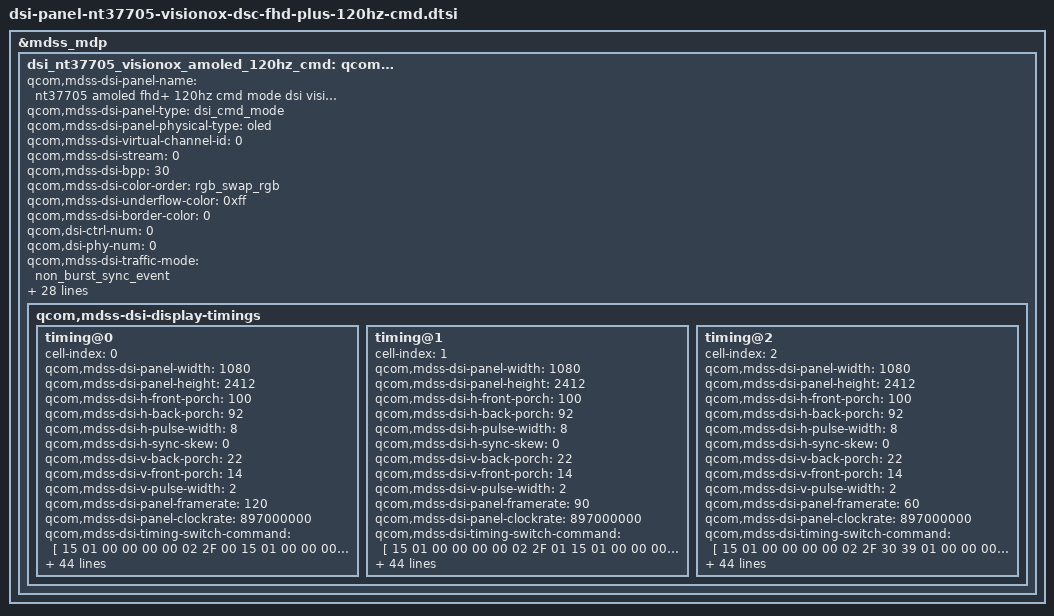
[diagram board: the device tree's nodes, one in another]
//OP Manual
//2023/5/12 update OP Manual v13
//1.switch DBV when Skip Frame 60hz/90hz, refresh rate will be changed to 60hz/90hz
//2023/4/25 update OP Manual v12
//1.add 51h setting code, it takes effects at second frame when write 51h
//2023/4/21 update OP Manual v11
//1.update Skip Frame mode setting code
//2023/4/20 update OP Manual v10
//1.update RCN code
//2.modify delay to 100ms after 11 code
//2023/3/30 update OP Manual v09
//1.update enter aod code and aod brightness code
//2023/3/13 update OP Manual v08
//1.update Skip Frame code
//2023/3/10 update OP Manual v07
//1.update OSC Tracking code
//2.enter Skip Frame mode when changing DBV, frequency returns to 120hz
//2023/2/27 update OP Manual v06
//1.add RCN code
//2023/2/14 update OP Manual v05
//1.modify enter/exit aod code
//2.modify skip frame CLKN code
//2023/2/6 update OP Manual v04
//1.Idle skip mode sequence: 30Hz(Repeat 1 times) --> 1Hz
//2.set OD ON
//3.add OSC tracking
//4.add skip frame CLKN slow down code(to solve esd issue)
//5.modify enter/exit aod code
//6.set DBV dimming OFF

&mdss_mdp {
	dsi_nt37705_visionox_amoled_120hz_cmd:
		qcom,mdss_dsi_nt37705_visionox_amoled_120hz_cmd {
		qcom,mdss-dsi-panel-name =
			"nt37705 amoled fhd+ 120hz cmd mode dsi visionox panel";
		qcom,mdss-dsi-panel-type = "dsi_cmd_mode";
		qcom,mdss-dsi-panel-physical-type = "oled";
		qcom,mdss-dsi-virtual-channel-id = <0>;
		qcom,mdss-dsi-stream = <0>;
		qcom,mdss-dsi-bpp = <30>;
		qcom,mdss-dsi-color-order = "rgb_swap_rgb";
		qcom,mdss-dsi-underflow-color = <0xff>;
		qcom,mdss-dsi-border-color = <0>;

		qcom,dsi-ctrl-num = <0>;
		qcom,dsi-phy-num = <0>;

		qcom,mdss-dsi-traffic-mode = "non_burst_sync_event";
		qcom,mdss-dsi-lane-map = "lane_map_0123";
		qcom,mdss-dsi-bllp-eof-power-mode;
		qcom,mdss-dsi-bllp-power-mode;
		qcom,mdss-dsi-lane-0-state;
		qcom,mdss-dsi-lane-1-state;
		qcom,mdss-dsi-lane-2-state;
		qcom,mdss-dsi-lane-3-state;
		qcom,mdss-dsi-dma-trigger = "trigger_sw";
		qcom,mdss-dsi-mdp-trigger = "none";
		qcom,mdss-dsi-lp11-init;
		qcom,mdss-dsi-reset-sequence = <1 10>, <0 1>, <1 20>;
		qcom,mdss-pan-physical-width-dimension = <69>;
		qcom,mdss-pan-physical-height-dimension = <156>;
		qcom,mdss-dsi-tx-eot-append;
		qcom,mdss-dsi-rx-eot-ignore;

		qcom,mdss-dsi-panel-hdr-enabled;
		qcom,mdss-dsi-panel-hdr-color-primaries = <14500 15500 32000
						17000 15500 30000 8000 3000>;
		qcom,mdss-dsi-panel-peak-brightness = <4200000>;
		qcom,mdss-dsi-panel-blackness-level = <3230>;

		qcom,mdss-dsi-te-pin-select = <1>;
		qcom,mdss-dsi-wr-mem-start = <0x2c>;
		qcom,mdss-dsi-wr-mem-continue = <0x3c>;
		qcom,mdss-dsi-te-dcs-command = <1>;
		qcom,mdss-dsi-te-check-enable;
		qcom,mdss-dsi-te-using-te-pin;
                qcom,fod-dim-lut = <
			1	254
			14	240
			28	240
			42	240
			56	239
			70	239
			84	239
			97	239
			111	238
			125	238
			139	237
			153	237
			167	237
			180	237
			194	236
			208	236
			222	236
			236	235
			250	235
			263	234
			277	234
			291	234
			305	233
			319	232
			333	232
			346	232
			360	232
			374	231
			388	230
			402	229
			416	229
			429	228
			443	228
			457	227
			471	226
			485	226
			499	225
			512	224
			526	224
			540	223
			554	222
			568	222
			582	221
			595	220
			609	219
			623	219
			637	218
			651	218
			665	217
			678	216
			692	216
			706	214
			720	214
			734	213
			748	213
			761	212
			775	211
			789	211
			803	210
			817	209
			831	208
			844	208
			858	207
			872	206
			886	205
			900	205
			914	203
			927	203
			941	202
			955	201
			969	201
			983	200
			997	200
			1010	199
			1024	198
			1038	198
			1052	197
			1066	196
			1080	195
			1093	195
			1107	194
			1121	193
			1135	192
			1149	192
			1163	191
			1176	190
			1190	189
			1204	189
			1218	188
			1232	187
			1246	186
			1259	186
			1273	185
			1287	184
			1301	183
			1315	183
			1329	182
			1342	181
			1356	181
			1370	180
			1384	179
			1398	179
			1412	178
			1425	177
			1439	176
			1453	176
			1467	175
			1481	174
			1495	174
			1508	173
			1522	172
			1536	171
			1550	171
			1564	170
			1578	170
			1591	169
			1605	169
			1619	168
			1633	167
			1647	167
			1661	166
			1674	166
			1688	165
			1702	164
			1716	164
			1730	163
			1744	163
			1758	162
			1771	161
			1785	161
			1799	160
			1813	159
			1827	159
			1841	158
			1854	157
			1868	156
			1882	156
			1896	155
			1910	154
			1924	153
			1937	153
			1951	152
			1965	151
			1979	150
			1993	150
			2007	149
			2020	148
			2034	147
			2048	146
			2062	146
			2076	145
			2090	145
			2103	144
			2117	143
			2131	143
			2145	142
			2159	141
			2173	141
			2186	140
			2200	139
			2214	139
			2228	138
			2242	137
			2256	137
			2269	136
			2283	135
			2297	135
			2311	134
			2325	133
			2339	133
			2352	132
			2366	131
			2380	131
			2394	130
			2408	129
			2422	129
			2435	128
			2449	127
			2463	126
			2477	126
			2491	125
			2505	124
			2518	124
			2532	123
			2546	122
			2560	121
			2574	121
			2588	120
			2601	119
			2615	119
			2629	118
			2643	117
			2657	117
			2671	116
			2684	115
			2698	114
			2712	114
			2726	113
			2740	112
			2754	112
			2767	111
			2781	110
			2795	110
			2809	109
			2823	108
			2837	107
			2850	107
			2864	106
			2878	105
			2892	104
			2906	104
			2920	103
			2933	102
			2947	101
			2961	101
			2975	100
			2989	99
			3003	98
			3016	98
			3030	97
			3044	96
			3058	95
			3072	94
			3086	94
			3099	93
			3113	92
			3127	92
			3141	91
			3155	90
			3169	89
			3182	89
			3196	88
			3210	87
			3224	86
			3238	85
			3252	85
			3265	84
			3279	83
			3293	82
			3307	82
			3321	81
			3335	80
			3348	80
			3362	79
			3376	78
			3390	77
			3404	76
			3418	76
			3431	75
			3445	74
			3459	74
			3473	73
			3487	72
			3501	71
			3515	70
		>;
		qcom,mdss-dsi-display-timings {
			timing@0 {
				cell-index = <0>;
				qcom,mdss-dsi-panel-width = <1080>;
				qcom,mdss-dsi-panel-height = <2412>;
				qcom,mdss-dsi-h-front-porch = <100>;
				qcom,mdss-dsi-h-back-porch = <92>;
				qcom,mdss-dsi-h-pulse-width = <8>;
				qcom,mdss-dsi-h-sync-skew = <0>;
				qcom,mdss-dsi-v-back-porch = <22>;
				qcom,mdss-dsi-v-front-porch = <14>;
				qcom,mdss-dsi-v-pulse-width = <2>;
				qcom,mdss-dsi-panel-framerate = <120>;
				qcom,mdss-dsi-panel-clockrate = <897000000>;

				qcom,mdss-dsi-timing-switch-command = [
						15 01 00 00 00 00 02 2F 00
						15 01 00 00 00 00 02 5A 00
						39 01 00 00 00 00 06 F0 55 AA 52 08 00
						39 01 00 00 00 00 02 6F C5
						39 01 00 00 00 00 02 BA 10
				];

				qcom,mdss-dsi-on-command = [
						39 01 00 00 00 00 06 F0 55 AA 52 08 00
						39 01 00 00 00 00 03 B5 80 00
						//RCN code
						39 01 00 00 00 00 06 F0 55 AA 52 08 07
						39 01 00 00 00 00 04 C0 87 01 08
						15 01 00 00 00 00 02 6F 03
						39 01 00 00 00 00 0F C0 00 00 00 55 00 00 00 00 00 00 00 00 00 00
						15 01 00 00 00 00 02 6F 00
						39 01 00 00 00 00 16 C1 30 0F 36 64 3B 19 8E 9C 3F C6 26 08 3F C3 FA 9C 00 0F 3D 5E 64
						15 01 00 00 00 00 02 6F 15
						39 01 00 00 00 00 11 C1 21 00 00 7B 00 00 82 33 F0 7E 85 3E 76 00 00 00
						15 01 00 00 00 00 02 6F 25
						39 01 00 00 00 00 11 C1 22 19 1F 00 21 2D 00 00 00 21 40 40 40 40 40 40
						15 01 00 00 00 00 02 6F 00
						39 01 00 00 00 00 16 C2 36 00 36 64 3B 19 71 64 00 05 95 E0 3F 8D 7F 90 00 00 00 00 00
						15 01 00 00 00 00 02 6F 15
						39 01 00 00 00 00 11 C2 21 34 BC 37 00 00 82 33 30 82 85 00 00 00 00 00
						15 01 00 00 00 00 02 6F 25
						39 01 00 00 00 00 11 C2 22 19 1F 00 4E 5A 00 00 00 21 40 40 40 40 40 40
						15 01 00 00 00 00 02 6F 00
						39 01 00 00 00 00 16 C3 2A 0F 36 64 3B 19 8E 9C 00 3F 2A A8 00 36 7B 0C 7F D5 18 25 84
						15 01 00 00 00 00 02 6F 15
						39 01 00 00 00 00 11 C3 60 34 BC 37 89 E9 6B 33 0F 82 7B C1 8A 00 00 00
						15 01 00 00 00 00 02 6F 25
						39 01 00 00 00 00 11 C3 00 00 00 00 00 00 00 00 00 60 40 40 40 40 40 40
						15 01 00 00 00 00 02 6F 00
						39 01 00 00 00 00 16 C4 2C 00 36 64 3B 19 71 64 3F 8C 91 40 00 00 00 00 00 00 00 00 00
						15 01 00 00 00 00 02 6F 15
						39 01 00 00 00 00 11 C4 60 00 00 7B 89 E9 6B 33 C0 7E 7B 00 00 00 00 00
						15 01 00 00 00 00 02 6F 25
						39 01 00 00 00 00 11 C4 00 00 00 00 00 00 00 00 00 60 40 40 40 40 40 40
						15 01 00 00 00 00 02 6F 00
						39 01 00 00 00 00 16 C5 21 00 03 49 03 49 00 00 3F FF 41 76 3F FF 41 76 00 00 0A CA D1
						15 01 00 00 00 00 02 6F 15
						39 01 00 00 00 00 11 C5 08 12 FE 1B 00 20 3D 33 F0 E3 E3 03 49 00 00 00
						15 01 00 00 00 00 02 6F 25
						39 01 00 00 00 00 11 C5 00 00 00 00 00 00 00 00 00 08 40 40 40 40 40 40
						15 01 00 00 00 00 02 6F 00
						39 01 00 00 00 00 16 C6 27 00 03 49 03 49 00 00 00 00 00 00 3F FF 41 76 00 00 00 00 00
						15 01 00 00 00 00 02 6F 15
						39 01 00 00 00 00 11 C6 08 22 1C 39 00 20 3D 33 30 1D E3 00 00 00 00 00
						15 01 00 00 00 00 02 6F 25
						39 01 00 00 00 00 11 C6 00 00 00 00 00 00 00 00 00 08 40 40 40 40 40 40
						15 01 00 00 00 00 02 6F 00
						39 01 00 00 00 00 16 C7 2B 00 03 49 03 49 00 00 00 00 00 00 00 00 00 00 7F FF F5 35 2F
						15 01 00 00 00 00 02 6F 15
						39 01 00 00 00 00 11 C7 14 22 1C 39 00 3E 5B 33 0F 1D 1D FC B7 00 00 00
						15 01 00 00 00 00 02 6F 25
						39 01 00 00 00 00 11 C7 00 00 00 00 00 00 00 00 00 14 40 40 40 40 40 40
						15 01 00 00 00 00 02 6F 00
						39 01 00 00 00 00 16 C8 2D 00 03 49 03 49 00 00 3F FF 41 76 00 00 00 00 00 00 00 00 00
						15 01 00 00 00 00 02 6F 15
						39 01 00 00 00 00 11 C8 14 12 FE 1B 00 3E 5B 33 C0 E3 1D 00 00 00 00 00
						15 01 00 00 00 00 02 6F 25
						39 01 00 00 00 00 11 C8 00 00 00 00 00 00 00 00 00 14 40 40 40 40 40 40
						15 01 00 00 00 00 02 6F 00
						39 01 00 00 00 00 16 C9 00 00 00 00 00 00 00 00 00 00 00 00 00 00 00 00 00 00 00 00 00
						15 01 00 00 00 00 02 6F 15
						39 01 00 00 00 00 11 C9 00 00 00 00 00 00 00 00 00 00 00 00 00 00 00 00
						15 01 00 00 00 00 02 6F 25
						39 01 00 00 00 00 11 C9 00 00 00 00 00 00 00 00 00 00 00 00 00 00 00 00
						15 01 00 00 00 00 02 6F 00
						39 01 00 00 00 00 16 CA 00 00 00 00 00 00 00 00 00 00 00 00 00 00 00 00 00 00 00 00 00
						15 01 00 00 00 00 02 6F 15
						39 01 00 00 00 00 11 CA 00 00 00 00 00 00 00 00 00 00 00 00 00 00 00 00
						15 01 00 00 00 00 02 6F 25
						39 01 00 00 00 00 11 CA 00 00 00 00 00 00 00 00 00 00 00 00 00 00 00 00
						15 01 00 00 00 00 02 6F 00
						39 01 00 00 00 00 16 CB 00 00 00 00 00 00 00 00 00 00 00 00 00 00 00 00 00 00 00 00 00
						15 01 00 00 00 00 02 6F 15
						39 01 00 00 00 00 11 CB 00 00 00 00 00 00 00 00 00 00 00 00 00 00 00 00
						15 01 00 00 00 00 02 6F 25
						39 01 00 00 00 00 11 CB 00 00 00 00 00 00 00 00 00 00 00 00 00 00 00 00
						15 01 00 00 00 00 02 6F 00
						39 01 00 00 00 00 16 CC 00 00 00 00 00 00 00 00 00 00 00 00 00 00 00 00 00 00 00 00 00
						15 01 00 00 00 00 02 6F 15
						39 01 00 00 00 00 11 CC 00 00 00 00 00 00 00 00 00 00 00 00 00 00 00 00
						15 01 00 00 00 00 02 6F 25
						39 01 00 00 00 00 11 CC 00 00 00 00 00 00 00 00 00 00 00 00 00 00 00 00
						//end RCN
						39 01 00 00 00 00 06 F0 55 AA 52 08 00
						39 01 00 00 00 00 02 6F 1B
						39 01 00 00 00 00 02 BA 18
						39 01 00 00 00 00 02 6F 1C
						39 01 00 00 00 00 11 BA 01 01 01 01 00 00 00 00 00 00 00 00 00 00 00 00
						39 01 00 00 00 00 02 6F 2C
						39 01 00 00 00 00 11 BA 00 01 01 01 00 01 01 01 00 01 01 01 00 00 00 00
						39 01 00 00 00 00 02 6F 3C
						39 01 00 00 00 00 11 BA 00 01 01 00 00 03 03 00 00 03 03 00 00 00 00 00
						39 01 00 00 00 00 02 6F 4C
						39 01 00 00 00 00 11 BA 00 01 00 00 00 0B 00 00 00 0B 00 00 00 00 00 00
						39 01 00 00 00 00 02 6F 5C
						39 01 00 00 00 00 11 BA 01 01 01 01 01 01 01 01 00 00 00 00 00 00 00 00
						39 01 00 00 00 00 02 6F 6C
						39 01 00 00 00 00 11 BA 01 02 00 04 0B 77 03 0B 00 00 00 00 00 00 00 00
						39 01 00 00 00 00 02 6F 7C
						39 01 00 00 00 00 11 BA 01 02 00 04 0B 77 03 0B 00 00 00 00 00 00 00 00
						39 01 00 00 00 00 02 6F 8C
						39 01 00 00 00 00 11 BA 00 00 00 00 00 00 00 00 00 00 00 00 00 00 00 00
						39 01 00 00 00 00 02 6F 9C
						39 01 00 00 00 00 09 BA 11 11 70 13 70 03 70 00
						39 01 00 00 00 00 02 6F A4
						39 01 00 00 00 00 05 BA 00 F6 00 00
						39 01 00 00 00 00 02 6F A8
						39 01 00 00 00 00 09 BA 00 00 00 00 00 00 00 00
						39 01 00 00 00 00 02 6F B0
						39 01 00 00 00 00 09 BA 00 00 00 00 00 00 00 00
						39 01 00 00 00 00 06 F0 55 AA 52 08 00
						39 01 00 00 00 00 02 6F 08
						39 01 00 00 00 00 05 BB 01 00 00 00
						39 01 00 00 00 00 02 6F 0C
						39 01 00 00 00 00 05 BB 00 00 00 00
						39 01 00 00 00 00 02 6F 10
						39 01 00 00 00 00 05 BB 00 00 00 00
						39 01 00 00 00 00 02 6F 14
						39 01 00 00 00 00 05 BB 00 00 00 00
						39 01 00 00 00 00 02 6F 18
						39 01 00 00 00 00 05 BB 01 1D 1D 00
						39 01 00 00 00 00 02 6F 1C
						39 01 00 00 00 00 03 BB 01 00
						39 01 00 00 00 00 06 F0 55 AA 52 08 01
						39 01 00 00 00 00 02 6F 05
						39 01 00 00 00 00 05 C5 15 15 15 dd
						39 01 00 00 00 00 06 F0 55 AA 52 08 03
						39 01 00 00 00 00 05 C3 02 32 22 22
						39 01 00 00 00 00 02 6F 06
						39 01 00 00 00 00 05 C3 02 32 22 22
						39 01 00 00 00 00 02 6F 0C
						39 01 00 00 00 00 02 C3 00
						39 01 00 00 00 00 06 F0 55 AA 52 08 01
						39 01 00 00 00 00 2A C3 DD 06 22 0E F4 00 06 20 0E FF 00 03 D0 0E 05 2C 13 03 D0 0E 05 2C 13 03 D0 0E 05 2C 13 03 D0 0E 05 2C 13 03 D0 0E 05 2C 13
						39 01 00 00 00 00 05 FF AA 55 A5 80
						39 01 00 00 00 00 02 6F 1A
						39 01 00 00 00 00 02 F4 55
						39 01 00 00 00 00 02 6F 1D
						39 01 00 00 00 00 02 F2 00
						39 01 00 00 00 00 02 6F 23
						39 01 00 00 00 00 02 F2 00
						39 01 00 00 00 00 02 6F 19
						39 01 00 00 00 00 02 F2 00
						39 01 00 00 00 00 02 6F 28
						39 01 00 00 00 00 02 F2 00
						39 01 00 00 00 00 02 6F 2C
						39 01 00 00 00 00 02 F2 00
						39 01 00 00 00 00 05 FF AA 55 A5 81
						39 01 00 00 00 00 02 6F 05
						39 01 00 00 00 00 02 FE 34
						39 01 00 00 00 00 02 6F 02
						39 01 00 00 00 00 02 F9 04
						39 01 00 00 00 00 02 6F 24
						39 01 00 00 00 00 15 FB 00 03 04 55 77 77 77 99 9B 10 00 1E 48 9A BB BC DE F0 11 30
						39 01 00 00 00 00 02 6F 19
						39 01 00 00 00 00 02 FB 30
						39 01 00 00 00 00 02 6F 1E
						39 01 00 00 00 00 02 FB 0F
						39 01 00 00 00 00 02 6F 0D
						39 01 00 00 00 00 02 FB 80
						39 01 00 00 00 00 02 6F 0A
						39 01 00 00 00 00 02 FD 08
						39 01 00 00 00 00 05 FF AA 55 A5 83
						39 01 00 00 00 00 02 6F 12
						39 01 00 00 00 00 02 FE 41
						39 01 00 00 00 00 05 FF AA 55 A5 80
						39 01 00 00 00 00 02 6F 31
						39 01 00 00 00 00 03 F8 00 FD
						39 01 00 00 00 00 05 FF AA 55 A5 80
						39 01 00 00 00 00 02 6F 15
						39 01 00 00 00 00 03 F8 01 4F
						39 01 00 00 00 00 06 F0 55 AA 52 08 01
						39 01 00 00 00 00 02 6F 03
						39 01 00 00 00 00 02 C7 07
						39 01 00 00 00 00 02 17 10
						39 01 00 00 00 00 05 2A 00 00 04 37
						39 01 00 00 00 00 05 2B 00 00 09 6B
						39 01 00 00 00 00 02 26 00
						39 01 00 00 00 00 02 2F 00
						39 01 00 00 00 00 02 35 00
						39 01 00 00 00 00 03 51 0D BB
						39 01 00 00 00 00 02 6F 04
						39 01 00 00 00 00 03 51 0F FF
						39 01 00 00 00 00 02 53 20
						39 01 00 00 00 00 06 F0 55 AA 52 08 00
						39 01 00 00 00 00 02 6F C5
						39 01 00 00 00 00 02 BA 10
						39 01 00 00 00 00 02 6D 00
						39 01 00 00 00 00 03 90 03 03
						39 01 00 00 00 00 13 91 AB 28 00 0C C2 00 02 0E 01 1F 00 07 08 BB 08 7A 10 F0
						05 01 00 00 64 00 01 11
						05 01 00 00 00 00 01 29
						39 01 00 00 00 00 06 F0 55 AA 52 08 08
						39 01 00 00 00 00 02 E0 01];
				qcom,mdss-dsi-off-command = [
						05 01 00 00 01 00 02 28 00
						05 01 00 00 64 00 02 10 00];
				qcom,mdss-dsi-on-command-state = "dsi_lp_mode";
				qcom,mdss-dsi-off-command-state = "dsi_hs_mode";

				qcom,mdss-dsi-aod-command-5nit = [
						39 01 00 00 00 00 02 6F 04
						39 01 00 00 00 00 03 51 01 55];
				qcom,mdss-dsi-aod-command-5nit-state = "dsi_lp_mode";
				qcom,mdss-dsi-aod-command-30nit = [
						39 01 00 00 00 00 02 6F 04
						39 01 00 00 00 00 03 51 08 00];
				qcom,mdss-dsi-aod-command-30nit-state = "dsi_lp_mode";
				qcom,mdss-dsi-aod-command-60nit = [
						39 01 00 00 00 00 02 6F 04
						39 01 00 00 00 00 03 51 0F FF];
				qcom,mdss-dsi-aod-command-60nit-state = "dsi_lp_mode";
				qcom,mdss-dsi-lp1-command-5nit = [
						39 01 00 00 00 00 02 6F 04
						39 01 00 00 00 00 03 51 01 55
						05 01 00 00 00 00 01 39
						39 01 00 00 00 00 01 2C
						39 01 00 00 00 00 02 2F 30
						39 01 00 00 00 00 03 6D 00 01];
				qcom,mdss-dsi-lp1-command-5nit-state = "dsi_lp_mode";
				qcom,mdss-dsi-lp1-command-30nit = [
						39 01 00 00 00 00 02 6F 04
						39 01 00 00 00 00 03 51 08 00
						05 01 00 00 00 00 01 39
						39 01 00 00 00 00 01 2C
						39 01 00 00 00 00 02 2F 30
						39 01 00 00 00 00 03 6D 00 01];
				qcom,mdss-dsi-lp1-command-30nit-state = "dsi_lp_mode";
				qcom,mdss-dsi-lp1-command-60nit = [
						39 01 00 00 00 00 02 6F 04
						39 01 00 00 00 00 03 51 0F FF
						05 01 00 00 00 00 01 39
						39 01 00 00 00 00 01 2C
						39 01 00 00 00 00 02 2F 30
						39 01 00 00 00 00 03 6D 00 01];
				qcom,mdss-dsi-lp1-command-60nit-state = "dsi_lp_mode";
				qcom,mdss-dsi-lp1-command = [
						39 01 00 00 00 00 02 6F 04
						39 01 00 00 00 00 03 51 0F FF
						05 01 00 00 00 00 01 39
						39 01 00 00 00 00 01 2C
						39 01 00 00 00 00 02 2F 30
						39 01 00 00 00 00 03 6D 00 01];
				qcom,mdss-dsi-lp1-command-state = "dsi_lp_mode";
				qcom,mdss-dsi-nolp-command = [
						05 01 00 00 00 00 01 38
						39 01 00 00 00 00 01 2C
						39 01 00 00 00 00 02 2F 00
						39 01 00 00 00 00 03 6D 00 00];
				qcom,mdss-dsi-nolp-command-state = "dsi_lp_mode";

				qcom,mdss-dsi-h-sync-pulse = <0>;
				qcom,compression-mode = "dsc";
				qcom,mdss-dsc-slice-height = <12>;
				qcom,mdss-dsc-slice-width = <540>;
				qcom,mdss-dsc-slice-per-pkt = <2>;
				qcom,mdss-dsc-bit-per-component = <10>;
				qcom,mdss-dsc-bit-per-pixel = <8>;
				qcom,mdss-dsc-block-prediction-enable;
			};
			timing@1 {
				cell-index = <1>;
				qcom,mdss-dsi-panel-width = <1080>;
				qcom,mdss-dsi-panel-height = <2412>;
				qcom,mdss-dsi-h-front-porch = <100>;
				qcom,mdss-dsi-h-back-porch = <92>;
				qcom,mdss-dsi-h-pulse-width = <8>;
				qcom,mdss-dsi-h-sync-skew = <0>;
				qcom,mdss-dsi-v-back-porch = <22>;
				qcom,mdss-dsi-v-front-porch = <14>;
				qcom,mdss-dsi-v-pulse-width = <2>;
				qcom,mdss-dsi-panel-framerate = <90>;
				qcom,mdss-dsi-panel-clockrate = <897000000>;

				qcom,mdss-dsi-timing-switch-command = [
						15 01 00 00 00 00 02 2F 01
						15 01 00 00 00 00 02 5A 00
						39 01 00 00 00 00 06 F0 55 AA 52 08 00
						39 01 00 00 00 00 02 6F C5
						39 01 00 00 00 00 02 BA 00
				];

				qcom,mdss-dsi-on-command = [
						39 01 00 00 00 00 06 F0 55 AA 52 08 00
						39 01 00 00 00 00 03 B5 80 00
						//RCN code
						39 01 00 00 00 00 06 F0 55 AA 52 08 07
						39 01 00 00 00 00 04 C0 87 01 08
						15 01 00 00 00 00 02 6F 03
						39 01 00 00 00 00 0F C0 00 00 00 55 00 00 00 00 00 00 00 00 00 00
						15 01 00 00 00 00 02 6F 00
						39 01 00 00 00 00 16 C1 30 0F 36 64 3B 19 8E 9C 3F C6 26 08 3F C3 FA 9C 00 0F 3D 5E 64
						15 01 00 00 00 00 02 6F 15
						39 01 00 00 00 00 11 C1 21 00 00 7B 00 00 82 33 F0 7E 85 3E 76 00 00 00
						15 01 00 00 00 00 02 6F 25
						39 01 00 00 00 00 11 C1 22 19 1F 00 21 2D 00 00 00 21 40 40 40 40 40 40
						15 01 00 00 00 00 02 6F 00
						39 01 00 00 00 00 16 C2 36 00 36 64 3B 19 71 64 00 05 95 E0 3F 8D 7F 90 00 00 00 00 00
						15 01 00 00 00 00 02 6F 15
						39 01 00 00 00 00 11 C2 21 34 BC 37 00 00 82 33 30 82 85 00 00 00 00 00
						15 01 00 00 00 00 02 6F 25
						39 01 00 00 00 00 11 C2 22 19 1F 00 4E 5A 00 00 00 21 40 40 40 40 40 40
						15 01 00 00 00 00 02 6F 00
						39 01 00 00 00 00 16 C3 2A 0F 36 64 3B 19 8E 9C 00 3F 2A A8 00 36 7B 0C 7F D5 18 25 84
						15 01 00 00 00 00 02 6F 15
						39 01 00 00 00 00 11 C3 60 34 BC 37 89 E9 6B 33 0F 82 7B C1 8A 00 00 00
						15 01 00 00 00 00 02 6F 25
						39 01 00 00 00 00 11 C3 00 00 00 00 00 00 00 00 00 60 40 40 40 40 40 40
						15 01 00 00 00 00 02 6F 00
						39 01 00 00 00 00 16 C4 2C 00 36 64 3B 19 71 64 3F 8C 91 40 00 00 00 00 00 00 00 00 00
						15 01 00 00 00 00 02 6F 15
						39 01 00 00 00 00 11 C4 60 00 00 7B 89 E9 6B 33 C0 7E 7B 00 00 00 00 00
						15 01 00 00 00 00 02 6F 25
						39 01 00 00 00 00 11 C4 00 00 00 00 00 00 00 00 00 60 40 40 40 40 40 40
						15 01 00 00 00 00 02 6F 00
						39 01 00 00 00 00 16 C5 21 00 03 49 03 49 00 00 3F FF 41 76 3F FF 41 76 00 00 0A CA D1
						15 01 00 00 00 00 02 6F 15
						39 01 00 00 00 00 11 C5 08 12 FE 1B 00 20 3D 33 F0 E3 E3 03 49 00 00 00
						15 01 00 00 00 00 02 6F 25
						39 01 00 00 00 00 11 C5 00 00 00 00 00 00 00 00 00 08 40 40 40 40 40 40
						15 01 00 00 00 00 02 6F 00
						39 01 00 00 00 00 16 C6 27 00 03 49 03 49 00 00 00 00 00 00 3F FF 41 76 00 00 00 00 00
						15 01 00 00 00 00 02 6F 15
						39 01 00 00 00 00 11 C6 08 22 1C 39 00 20 3D 33 30 1D E3 00 00 00 00 00
						15 01 00 00 00 00 02 6F 25
						39 01 00 00 00 00 11 C6 00 00 00 00 00 00 00 00 00 08 40 40 40 40 40 40
						15 01 00 00 00 00 02 6F 00
						39 01 00 00 00 00 16 C7 2B 00 03 49 03 49 00 00 00 00 00 00 00 00 00 00 7F FF F5 35 2F
						15 01 00 00 00 00 02 6F 15
						39 01 00 00 00 00 11 C7 14 22 1C 39 00 3E 5B 33 0F 1D 1D FC B7 00 00 00
						15 01 00 00 00 00 02 6F 25
						39 01 00 00 00 00 11 C7 00 00 00 00 00 00 00 00 00 14 40 40 40 40 40 40
						15 01 00 00 00 00 02 6F 00
						39 01 00 00 00 00 16 C8 2D 00 03 49 03 49 00 00 3F FF 41 76 00 00 00 00 00 00 00 00 00
						15 01 00 00 00 00 02 6F 15
						39 01 00 00 00 00 11 C8 14 12 FE 1B 00 3E 5B 33 C0 E3 1D 00 00 00 00 00
						15 01 00 00 00 00 02 6F 25
						39 01 00 00 00 00 11 C8 00 00 00 00 00 00 00 00 00 14 40 40 40 40 40 40
						15 01 00 00 00 00 02 6F 00
						39 01 00 00 00 00 16 C9 00 00 00 00 00 00 00 00 00 00 00 00 00 00 00 00 00 00 00 00 00
						15 01 00 00 00 00 02 6F 15
						39 01 00 00 00 00 11 C9 00 00 00 00 00 00 00 00 00 00 00 00 00 00 00 00
						15 01 00 00 00 00 02 6F 25
						39 01 00 00 00 00 11 C9 00 00 00 00 00 00 00 00 00 00 00 00 00 00 00 00
						15 01 00 00 00 00 02 6F 00
						39 01 00 00 00 00 16 CA 00 00 00 00 00 00 00 00 00 00 00 00 00 00 00 00 00 00 00 00 00
						15 01 00 00 00 00 02 6F 15
						39 01 00 00 00 00 11 CA 00 00 00 00 00 00 00 00 00 00 00 00 00 00 00 00
						15 01 00 00 00 00 02 6F 25
						39 01 00 00 00 00 11 CA 00 00 00 00 00 00 00 00 00 00 00 00 00 00 00 00
						15 01 00 00 00 00 02 6F 00
						39 01 00 00 00 00 16 CB 00 00 00 00 00 00 00 00 00 00 00 00 00 00 00 00 00 00 00 00 00
						15 01 00 00 00 00 02 6F 15
						39 01 00 00 00 00 11 CB 00 00 00 00 00 00 00 00 00 00 00 00 00 00 00 00
						15 01 00 00 00 00 02 6F 25
						39 01 00 00 00 00 11 CB 00 00 00 00 00 00 00 00 00 00 00 00 00 00 00 00
						15 01 00 00 00 00 02 6F 00
						39 01 00 00 00 00 16 CC 00 00 00 00 00 00 00 00 00 00 00 00 00 00 00 00 00 00 00 00 00
						15 01 00 00 00 00 02 6F 15
						39 01 00 00 00 00 11 CC 00 00 00 00 00 00 00 00 00 00 00 00 00 00 00 00
						15 01 00 00 00 00 02 6F 25
						39 01 00 00 00 00 11 CC 00 00 00 00 00 00 00 00 00 00 00 00 00 00 00 00
						//end RCN
						39 01 00 00 00 00 06 F0 55 AA 52 08 00
						39 01 00 00 00 00 02 6F 1B
						39 01 00 00 00 00 02 BA 18
						39 01 00 00 00 00 02 6F 1C
						39 01 00 00 00 00 11 BA 01 01 01 01 00 00 00 00 00 00 00 00 00 00 00 00
						39 01 00 00 00 00 02 6F 2C
						39 01 00 00 00 00 11 BA 00 01 01 01 00 01 01 01 00 01 01 01 00 00 00 00
						39 01 00 00 00 00 02 6F 3C
						39 01 00 00 00 00 11 BA 00 01 01 00 00 03 03 00 00 03 03 00 00 00 00 00
						39 01 00 00 00 00 02 6F 4C
						39 01 00 00 00 00 11 BA 00 01 00 00 00 0B 00 00 00 0B 00 00 00 00 00 00
						39 01 00 00 00 00 02 6F 5C
						39 01 00 00 00 00 11 BA 01 01 01 01 01 01 01 01 00 00 00 00 00 00 00 00
						39 01 00 00 00 00 02 6F 6C
						39 01 00 00 00 00 11 BA 01 02 00 04 0B 77 03 0B 00 00 00 00 00 00 00 00
						39 01 00 00 00 00 02 6F 7C
						39 01 00 00 00 00 11 BA 01 02 00 04 0B 77 03 0B 00 00 00 00 00 00 00 00
						39 01 00 00 00 00 02 6F 8C
						39 01 00 00 00 00 11 BA 00 00 00 00 00 00 00 00 00 00 00 00 00 00 00 00
						39 01 00 00 00 00 02 6F 9C
						39 01 00 00 00 00 09 BA 11 11 70 13 70 03 70 00
						39 01 00 00 00 00 02 6F A4
						39 01 00 00 00 00 05 BA 00 F6 00 00
						39 01 00 00 00 00 02 6F A8
						39 01 00 00 00 00 09 BA 00 00 00 00 00 00 00 00
						39 01 00 00 00 00 02 6F B0
						39 01 00 00 00 00 09 BA 00 00 00 00 00 00 00 00
						39 01 00 00 00 00 06 F0 55 AA 52 08 00
						39 01 00 00 00 00 02 6F 08
						39 01 00 00 00 00 05 BB 01 00 00 00
						39 01 00 00 00 00 02 6F 0C
						39 01 00 00 00 00 05 BB 00 00 00 00
						39 01 00 00 00 00 02 6F 10
						39 01 00 00 00 00 05 BB 00 00 00 00
						39 01 00 00 00 00 02 6F 14
						39 01 00 00 00 00 05 BB 00 00 00 00
						39 01 00 00 00 00 02 6F 18
						39 01 00 00 00 00 05 BB 01 1D 1D 00
						39 01 00 00 00 00 02 6F 1C
						39 01 00 00 00 00 03 BB 01 00
						39 01 00 00 00 00 06 F0 55 AA 52 08 01
						39 01 00 00 00 00 02 6F 05
						39 01 00 00 00 00 05 C5 15 15 15 dd
						39 01 00 00 00 00 06 F0 55 AA 52 08 03
						39 01 00 00 00 00 05 C3 02 32 22 22
						39 01 00 00 00 00 02 6F 06
						39 01 00 00 00 00 05 C3 02 32 22 22
						39 01 00 00 00 00 02 6F 0C
						39 01 00 00 00 00 02 C3 00
						39 01 00 00 00 00 06 F0 55 AA 52 08 01
						39 01 00 00 00 00 2A C3 DD 06 22 0E F4 00 06 20 0E FF 00 03 D0 0E 05 2C 13 03 D0 0E 05 2C 13 03 D0 0E 05 2C 13 03 D0 0E 05 2C 13 03 D0 0E 05 2C 13
						39 01 00 00 00 00 05 FF AA 55 A5 80
						39 01 00 00 00 00 02 6F 1A
						39 01 00 00 00 00 02 F4 55
						39 01 00 00 00 00 02 6F 1D
						39 01 00 00 00 00 02 F2 00
						39 01 00 00 00 00 02 6F 23
						39 01 00 00 00 00 02 F2 00
						39 01 00 00 00 00 02 6F 19
						39 01 00 00 00 00 02 F2 00
						39 01 00 00 00 00 02 6F 28
						39 01 00 00 00 00 02 F2 00
						39 01 00 00 00 00 02 6F 2C
						39 01 00 00 00 00 02 F2 00
						39 01 00 00 00 00 05 FF AA 55 A5 81
						39 01 00 00 00 00 02 6F 05
						39 01 00 00 00 00 02 FE 34
						39 01 00 00 00 00 02 6F 02
						39 01 00 00 00 00 02 F9 04
						39 01 00 00 00 00 02 6F 24
						39 01 00 00 00 00 15 FB 00 03 04 55 77 77 77 99 9B 10 00 1E 48 9A BB BC DE F0 11 30
						39 01 00 00 00 00 02 6F 19
						39 01 00 00 00 00 02 FB 30
						39 01 00 00 00 00 02 6F 1E
						39 01 00 00 00 00 02 FB 0F
						39 01 00 00 00 00 02 6F 0D
						39 01 00 00 00 00 02 FB 80
						39 01 00 00 00 00 02 6F 0A
						39 01 00 00 00 00 02 FD 08
						39 01 00 00 00 00 05 FF AA 55 A5 83
						39 01 00 00 00 00 02 6F 12
						39 01 00 00 00 00 02 FE 41
						39 01 00 00 00 00 05 FF AA 55 A5 80
						39 01 00 00 00 00 02 6F 31
						39 01 00 00 00 00 03 F8 00 FD
						39 01 00 00 00 00 05 FF AA 55 A5 80
						39 01 00 00 00 00 02 6F 15
						39 01 00 00 00 00 03 F8 01 4F
						39 01 00 00 00 00 06 F0 55 AA 52 08 01
						39 01 00 00 00 00 02 6F 03
						39 01 00 00 00 00 02 C7 07
						39 01 00 00 00 00 02 17 10
						39 01 00 00 00 00 05 2A 00 00 04 37
						39 01 00 00 00 00 05 2B 00 00 09 6B
						39 01 00 00 00 00 02 26 00
						39 01 00 00 00 00 02 2F 01
						39 01 00 00 00 00 02 35 00
						39 01 00 00 00 00 03 51 0D BB
						39 01 00 00 00 00 02 6F 04
						39 01 00 00 00 00 03 51 0F FF
						39 01 00 00 00 00 02 53 20
						39 01 00 00 00 00 06 F0 55 AA 52 08 00
						39 01 00 00 00 00 02 6F C5
						39 01 00 00 00 00 02 BA 00
						39 01 00 00 00 00 02 6D 00
						39 01 00 00 00 00 03 90 03 03
						39 01 00 00 00 00 13 91 AB 28 00 0C C2 00 02 0E 01 1F 00 07 08 BB 08 7A 10 F0
						05 01 00 00 64 00 01 11
						05 01 00 00 00 00 01 29
						39 01 00 00 00 00 06 F0 55 AA 52 08 08
						39 01 00 00 00 00 02 E0 01];
				qcom,mdss-dsi-off-command = [
						05 01 00 00 01 00 02 28 00
						05 01 00 00 64 00 02 10 00];
				qcom,mdss-dsi-on-command-state = "dsi_lp_mode";
				qcom,mdss-dsi-off-command-state = "dsi_hs_mode";

				qcom,mdss-dsi-aod-command-5nit = [
						39 01 00 00 00 00 02 6F 04
						39 01 00 00 00 00 03 51 01 55];
				qcom,mdss-dsi-aod-command-5nit-state = "dsi_lp_mode";
				qcom,mdss-dsi-aod-command-30nit = [
						39 01 00 00 00 00 02 6F 04
						39 01 00 00 00 00 03 51 08 00];
				qcom,mdss-dsi-aod-command-30nit-state = "dsi_lp_mode";
				qcom,mdss-dsi-aod-command-60nit = [
						39 01 00 00 00 00 02 6F 04
						39 01 00 00 00 00 03 51 0F FF];
				qcom,mdss-dsi-aod-command-60nit-state = "dsi_lp_mode";
				qcom,mdss-dsi-lp1-command-5nit = [
						39 01 00 00 00 00 02 6F 04
						39 01 00 00 00 00 03 51 01 55
						05 01 00 00 00 00 01 39
						39 01 00 00 00 00 01 2C
						39 01 00 00 00 00 02 2F 30
						39 01 00 00 00 00 03 6D 00 01];
				qcom,mdss-dsi-lp1-command-5nit-state = "dsi_lp_mode";
				qcom,mdss-dsi-lp1-command-30nit = [
						39 01 00 00 00 00 02 6F 04
						39 01 00 00 00 00 03 51 08 00
						05 01 00 00 00 00 01 39
						39 01 00 00 00 00 01 2C
						39 01 00 00 00 00 02 2F 30
						39 01 00 00 00 00 03 6D 00 01];
				qcom,mdss-dsi-lp1-command-30nit-state = "dsi_lp_mode";
				qcom,mdss-dsi-lp1-command-60nit = [
						39 01 00 00 00 00 02 6F 04
						39 01 00 00 00 00 03 51 0F FF
						05 01 00 00 00 00 01 39
						39 01 00 00 00 00 01 2C
						39 01 00 00 00 00 02 2F 30
						39 01 00 00 00 00 03 6D 00 01];
				qcom,mdss-dsi-lp1-command-60nit-state = "dsi_lp_mode";
				qcom,mdss-dsi-lp1-command = [
						39 01 00 00 00 00 02 6F 04
						39 01 00 00 00 00 03 51 0F FF
						05 01 00 00 00 00 01 39
						39 01 00 00 00 00 01 2C
						39 01 00 00 00 00 02 2F 30
						39 01 00 00 00 00 03 6D 00 01];
				qcom,mdss-dsi-lp1-command-state = "dsi_lp_mode";
				qcom,mdss-dsi-nolp-command = [
						05 01 00 00 00 00 01 38
						39 01 00 00 00 00 01 2C
						39 01 00 00 00 00 02 2F 01
						39 01 00 00 00 00 03 6D 00 00];
				qcom,mdss-dsi-nolp-command-state = "dsi_lp_mode";

				qcom,mdss-dsi-h-sync-pulse = <0>;
				qcom,compression-mode = "dsc";
				qcom,mdss-dsc-slice-height = <12>;
				qcom,mdss-dsc-slice-width = <540>;
				qcom,mdss-dsc-slice-per-pkt = <2>;
				qcom,mdss-dsc-bit-per-component = <10>;
				qcom,mdss-dsc-bit-per-pixel = <8>;
				qcom,mdss-dsc-block-prediction-enable;
			};
			timing@2 {
				cell-index = <2>;
				qcom,mdss-dsi-panel-width = <1080>;
				qcom,mdss-dsi-panel-height = <2412>;
				qcom,mdss-dsi-h-front-porch = <100>;
				qcom,mdss-dsi-h-back-porch = <92>;
				qcom,mdss-dsi-h-pulse-width = <8>;
				qcom,mdss-dsi-h-sync-skew = <0>;
				qcom,mdss-dsi-v-back-porch = <22>;
				qcom,mdss-dsi-v-front-porch = <14>;
				qcom,mdss-dsi-v-pulse-width = <2>;
				qcom,mdss-dsi-panel-framerate = <60>;
				qcom,mdss-dsi-panel-clockrate = <897000000>;

				qcom,mdss-dsi-timing-switch-command = [
						15 01 00 00 00 00 02 2F 30
						39 01 00 00 00 00 03 6D 00 00
						15 01 00 00 00 00 02 5A 01
						39 01 00 00 00 00 06 F0 55 AA 52 08 00
						39 01 00 00 00 00 02 6F C5
						39 01 00 00 00 00 02 BA 00
				];

				qcom,mdss-dsi-on-command = [
						39 01 00 00 00 00 06 F0 55 AA 52 08 00
						39 01 00 00 00 00 03 B5 80 00
						//RCN code
						39 01 00 00 00 00 06 F0 55 AA 52 08 07
						39 01 00 00 00 00 04 C0 87 01 08
						15 01 00 00 00 00 02 6F 03
						39 01 00 00 00 00 0F C0 00 00 00 55 00 00 00 00 00 00 00 00 00 00
						15 01 00 00 00 00 02 6F 00
						39 01 00 00 00 00 16 C1 30 0F 36 64 3B 19 8E 9C 3F C6 26 08 3F C3 FA 9C 00 0F 3D 5E 64
						15 01 00 00 00 00 02 6F 15
						39 01 00 00 00 00 11 C1 21 00 00 7B 00 00 82 33 F0 7E 85 3E 76 00 00 00
						15 01 00 00 00 00 02 6F 25
						39 01 00 00 00 00 11 C1 22 19 1F 00 21 2D 00 00 00 21 40 40 40 40 40 40
						15 01 00 00 00 00 02 6F 00
						39 01 00 00 00 00 16 C2 36 00 36 64 3B 19 71 64 00 05 95 E0 3F 8D 7F 90 00 00 00 00 00
						15 01 00 00 00 00 02 6F 15
						39 01 00 00 00 00 11 C2 21 34 BC 37 00 00 82 33 30 82 85 00 00 00 00 00
						15 01 00 00 00 00 02 6F 25
						39 01 00 00 00 00 11 C2 22 19 1F 00 4E 5A 00 00 00 21 40 40 40 40 40 40
						15 01 00 00 00 00 02 6F 00
						39 01 00 00 00 00 16 C3 2A 0F 36 64 3B 19 8E 9C 00 3F 2A A8 00 36 7B 0C 7F D5 18 25 84
						15 01 00 00 00 00 02 6F 15
						39 01 00 00 00 00 11 C3 60 34 BC 37 89 E9 6B 33 0F 82 7B C1 8A 00 00 00
						15 01 00 00 00 00 02 6F 25
						39 01 00 00 00 00 11 C3 00 00 00 00 00 00 00 00 00 60 40 40 40 40 40 40
						15 01 00 00 00 00 02 6F 00
						39 01 00 00 00 00 16 C4 2C 00 36 64 3B 19 71 64 3F 8C 91 40 00 00 00 00 00 00 00 00 00
						15 01 00 00 00 00 02 6F 15
						39 01 00 00 00 00 11 C4 60 00 00 7B 89 E9 6B 33 C0 7E 7B 00 00 00 00 00
						15 01 00 00 00 00 02 6F 25
						39 01 00 00 00 00 11 C4 00 00 00 00 00 00 00 00 00 60 40 40 40 40 40 40
						15 01 00 00 00 00 02 6F 00
						39 01 00 00 00 00 16 C5 21 00 03 49 03 49 00 00 3F FF 41 76 3F FF 41 76 00 00 0A CA D1
						15 01 00 00 00 00 02 6F 15
						39 01 00 00 00 00 11 C5 08 12 FE 1B 00 20 3D 33 F0 E3 E3 03 49 00 00 00
						15 01 00 00 00 00 02 6F 25
						39 01 00 00 00 00 11 C5 00 00 00 00 00 00 00 00 00 08 40 40 40 40 40 40
						15 01 00 00 00 00 02 6F 00
						39 01 00 00 00 00 16 C6 27 00 03 49 03 49 00 00 00 00 00 00 3F FF 41 76 00 00 00 00 00
						15 01 00 00 00 00 02 6F 15
						39 01 00 00 00 00 11 C6 08 22 1C 39 00 20 3D 33 30 1D E3 00 00 00 00 00
						15 01 00 00 00 00 02 6F 25
						39 01 00 00 00 00 11 C6 00 00 00 00 00 00 00 00 00 08 40 40 40 40 40 40
						15 01 00 00 00 00 02 6F 00
						39 01 00 00 00 00 16 C7 2B 00 03 49 03 49 00 00 00 00 00 00 00 00 00 00 7F FF F5 35 2F
						15 01 00 00 00 00 02 6F 15
						39 01 00 00 00 00 11 C7 14 22 1C 39 00 3E 5B 33 0F 1D 1D FC B7 00 00 00
						15 01 00 00 00 00 02 6F 25
						39 01 00 00 00 00 11 C7 00 00 00 00 00 00 00 00 00 14 40 40 40 40 40 40
						15 01 00 00 00 00 02 6F 00
						39 01 00 00 00 00 16 C8 2D 00 03 49 03 49 00 00 3F FF 41 76 00 00 00 00 00 00 00 00 00
						15 01 00 00 00 00 02 6F 15
						39 01 00 00 00 00 11 C8 14 12 FE 1B 00 3E 5B 33 C0 E3 1D 00 00 00 00 00
						15 01 00 00 00 00 02 6F 25
						39 01 00 00 00 00 11 C8 00 00 00 00 00 00 00 00 00 14 40 40 40 40 40 40
						15 01 00 00 00 00 02 6F 00
						39 01 00 00 00 00 16 C9 00 00 00 00 00 00 00 00 00 00 00 00 00 00 00 00 00 00 00 00 00
						15 01 00 00 00 00 02 6F 15
						39 01 00 00 00 00 11 C9 00 00 00 00 00 00 00 00 00 00 00 00 00 00 00 00
						15 01 00 00 00 00 02 6F 25
						39 01 00 00 00 00 11 C9 00 00 00 00 00 00 00 00 00 00 00 00 00 00 00 00
						15 01 00 00 00 00 02 6F 00
						39 01 00 00 00 00 16 CA 00 00 00 00 00 00 00 00 00 00 00 00 00 00 00 00 00 00 00 00 00
						15 01 00 00 00 00 02 6F 15
						39 01 00 00 00 00 11 CA 00 00 00 00 00 00 00 00 00 00 00 00 00 00 00 00
						15 01 00 00 00 00 02 6F 25
						39 01 00 00 00 00 11 CA 00 00 00 00 00 00 00 00 00 00 00 00 00 00 00 00
						15 01 00 00 00 00 02 6F 00
						39 01 00 00 00 00 16 CB 00 00 00 00 00 00 00 00 00 00 00 00 00 00 00 00 00 00 00 00 00
						15 01 00 00 00 00 02 6F 15
						39 01 00 00 00 00 11 CB 00 00 00 00 00 00 00 00 00 00 00 00 00 00 00 00
						15 01 00 00 00 00 02 6F 25
						39 01 00 00 00 00 11 CB 00 00 00 00 00 00 00 00 00 00 00 00 00 00 00 00
						15 01 00 00 00 00 02 6F 00
						39 01 00 00 00 00 16 CC 00 00 00 00 00 00 00 00 00 00 00 00 00 00 00 00 00 00 00 00 00
						15 01 00 00 00 00 02 6F 15
						39 01 00 00 00 00 11 CC 00 00 00 00 00 00 00 00 00 00 00 00 00 00 00 00
						15 01 00 00 00 00 02 6F 25
						39 01 00 00 00 00 11 CC 00 00 00 00 00 00 00 00 00 00 00 00 00 00 00 00
						//end RCN
						39 01 00 00 00 00 06 F0 55 AA 52 08 00
						39 01 00 00 00 00 02 6F 1B
						39 01 00 00 00 00 02 BA 18
						39 01 00 00 00 00 02 6F 1C
						39 01 00 00 00 00 11 BA 01 01 01 01 00 00 00 00 00 00 00 00 00 00 00 00
						39 01 00 00 00 00 02 6F 2C
						39 01 00 00 00 00 11 BA 00 01 01 01 00 01 01 01 00 01 01 01 00 00 00 00
						39 01 00 00 00 00 02 6F 3C
						39 01 00 00 00 00 11 BA 00 01 01 00 00 03 03 00 00 03 03 00 00 00 00 00
						39 01 00 00 00 00 02 6F 4C
						39 01 00 00 00 00 11 BA 00 01 00 00 00 0B 00 00 00 0B 00 00 00 00 00 00
						39 01 00 00 00 00 02 6F 5C
						39 01 00 00 00 00 11 BA 01 01 01 01 01 01 01 01 00 00 00 00 00 00 00 00
						39 01 00 00 00 00 02 6F 6C
						39 01 00 00 00 00 11 BA 01 02 00 04 0B 77 03 0B 00 00 00 00 00 00 00 00
						39 01 00 00 00 00 02 6F 7C
						39 01 00 00 00 00 11 BA 01 02 00 04 0B 77 03 0B 00 00 00 00 00 00 00 00
						39 01 00 00 00 00 02 6F 8C
						39 01 00 00 00 00 11 BA 00 00 00 00 00 00 00 00 00 00 00 00 00 00 00 00
						39 01 00 00 00 00 02 6F 9C
						39 01 00 00 00 00 09 BA 11 11 70 13 70 03 70 00
						39 01 00 00 00 00 02 6F A4
						39 01 00 00 00 00 05 BA 00 F6 00 00
						39 01 00 00 00 00 02 6F A8
						39 01 00 00 00 00 09 BA 00 00 00 00 00 00 00 00
						39 01 00 00 00 00 02 6F B0
						39 01 00 00 00 00 09 BA 00 00 00 00 00 00 00 00
						39 01 00 00 00 00 06 F0 55 AA 52 08 00
						39 01 00 00 00 00 02 6F 08
						39 01 00 00 00 00 05 BB 01 00 00 00
						39 01 00 00 00 00 02 6F 0C
						39 01 00 00 00 00 05 BB 00 00 00 00
						39 01 00 00 00 00 02 6F 10
						39 01 00 00 00 00 05 BB 00 00 00 00
						39 01 00 00 00 00 02 6F 14
						39 01 00 00 00 00 05 BB 00 00 00 00
						39 01 00 00 00 00 02 6F 18
						39 01 00 00 00 00 05 BB 01 1D 1D 00
						39 01 00 00 00 00 02 6F 1C
						39 01 00 00 00 00 03 BB 01 00
						39 01 00 00 00 00 06 F0 55 AA 52 08 01
						39 01 00 00 00 00 02 6F 05
						39 01 00 00 00 00 05 C5 15 15 15 dd
						39 01 00 00 00 00 06 F0 55 AA 52 08 03
						39 01 00 00 00 00 05 C3 02 32 22 22
						39 01 00 00 00 00 02 6F 06
						39 01 00 00 00 00 05 C3 02 32 22 22
						39 01 00 00 00 00 02 6F 0C
						39 01 00 00 00 00 02 C3 00
						39 01 00 00 00 00 06 F0 55 AA 52 08 01
						39 01 00 00 00 00 2A C3 DD 06 22 0E F4 00 06 20 0E FF 00 03 D0 0E 05 2C 13 03 D0 0E 05 2C 13 03 D0 0E 05 2C 13 03 D0 0E 05 2C 13 03 D0 0E 05 2C 13
						39 01 00 00 00 00 05 FF AA 55 A5 80
						39 01 00 00 00 00 02 6F 1A
						39 01 00 00 00 00 02 F4 55
						39 01 00 00 00 00 02 6F 1D
						39 01 00 00 00 00 02 F2 00
						39 01 00 00 00 00 02 6F 23
						39 01 00 00 00 00 02 F2 00
						39 01 00 00 00 00 02 6F 19
						39 01 00 00 00 00 02 F2 00
						39 01 00 00 00 00 02 6F 28
						39 01 00 00 00 00 02 F2 00
						39 01 00 00 00 00 02 6F 2C
						39 01 00 00 00 00 02 F2 00
						39 01 00 00 00 00 05 FF AA 55 A5 81
						39 01 00 00 00 00 02 6F 05
						39 01 00 00 00 00 02 FE 34
						39 01 00 00 00 00 02 6F 02
						39 01 00 00 00 00 02 F9 04
						39 01 00 00 00 00 02 6F 24
						39 01 00 00 00 00 15 FB 00 03 04 55 77 77 77 99 9B 10 00 1E 48 9A BB BC DE F0 11 30
						39 01 00 00 00 00 02 6F 19
						39 01 00 00 00 00 02 FB 30
						39 01 00 00 00 00 02 6F 1E
						39 01 00 00 00 00 02 FB 0F
						39 01 00 00 00 00 02 6F 0D
						39 01 00 00 00 00 02 FB 80
						39 01 00 00 00 00 02 6F 0A
						39 01 00 00 00 00 02 FD 08
						39 01 00 00 00 00 05 FF AA 55 A5 83
						39 01 00 00 00 00 02 6F 12
						39 01 00 00 00 00 02 FE 41
						39 01 00 00 00 00 05 FF AA 55 A5 80
						39 01 00 00 00 00 02 6F 31
						39 01 00 00 00 00 03 F8 00 FD
						39 01 00 00 00 00 05 FF AA 55 A5 80
						39 01 00 00 00 00 02 6F 15
						39 01 00 00 00 00 03 F8 01 4F
						39 01 00 00 00 00 06 F0 55 AA 52 08 01
						39 01 00 00 00 00 02 6F 03
						39 01 00 00 00 00 02 C7 07
						39 01 00 00 00 00 02 17 10
						39 01 00 00 00 00 05 2A 00 00 04 37
						39 01 00 00 00 00 05 2B 00 00 09 6B
						39 01 00 00 00 00 02 26 00
						15 01 00 00 00 00 02 2F 30
						39 01 00 00 00 00 03 6D 00 00
						15 01 00 00 00 00 02 5A 01
						39 01 00 00 00 00 02 35 00
						39 01 00 00 00 00 03 51 0D BB
						39 01 00 00 00 00 02 6F 04
						39 01 00 00 00 00 03 51 0F FF
						39 01 00 00 00 00 02 53 20
						39 01 00 00 00 00 06 F0 55 AA 52 08 00
						39 01 00 00 00 00 02 6F C5
						39 01 00 00 00 00 02 BA 00
						39 01 00 00 00 00 02 6D 00
						39 01 00 00 00 00 03 90 03 03
						39 01 00 00 00 00 13 91 AB 28 00 0C C2 00 02 0E 01 1F 00 07 08 BB 08 7A 10 F0
						05 01 00 00 64 00 01 11
						05 01 00 00 00 00 01 29
						39 01 00 00 00 00 06 F0 55 AA 52 08 08
						39 01 00 00 00 00 02 E0 01];
				qcom,mdss-dsi-off-command = [
						05 01 00 00 01 00 02 28 00
						05 01 00 00 64 00 02 10 00];
				qcom,mdss-dsi-on-command-state = "dsi_lp_mode";
				qcom,mdss-dsi-off-command-state = "dsi_hs_mode";

				qcom,mdss-dsi-aod-command-5nit = [
						39 01 00 00 00 00 02 6F 04
						39 01 00 00 00 00 03 51 01 55];
				qcom,mdss-dsi-aod-command-5nit-state = "dsi_lp_mode";
				qcom,mdss-dsi-aod-command-30nit = [
						39 01 00 00 00 00 02 6F 04
						39 01 00 00 00 00 03 51 08 00];
				qcom,mdss-dsi-aod-command-30nit-state = "dsi_lp_mode";
				qcom,mdss-dsi-aod-command-60nit = [
						39 01 00 00 00 00 02 6F 04
						39 01 00 00 00 00 03 51 0F FF];
				qcom,mdss-dsi-aod-command-60nit-state = "dsi_lp_mode";
				qcom,mdss-dsi-lp1-command-5nit = [
						15 01 00 00 00 00 02 5A 00
						39 01 00 00 00 00 02 6F 04
						39 01 00 00 00 00 03 51 01 55
						05 01 00 00 00 00 01 39
						39 01 00 00 00 00 01 2C
						39 01 00 00 00 00 03 6D 00 01];
				qcom,mdss-dsi-lp1-command-5nit-state = "dsi_lp_mode";
				qcom,mdss-dsi-lp1-command-30nit = [
						15 01 00 00 00 00 02 5A 00
						39 01 00 00 00 00 02 6F 04
						39 01 00 00 00 00 03 51 08 00
						05 01 00 00 00 00 01 39
						39 01 00 00 00 00 01 2C
						39 01 00 00 00 00 03 6D 00 01];
				qcom,mdss-dsi-lp1-command-30nit-state = "dsi_lp_mode";
				qcom,mdss-dsi-lp1-command-60nit = [
						15 01 00 00 00 00 02 5A 00
						39 01 00 00 00 00 02 6F 04
						39 01 00 00 00 00 03 51 0F FF
						05 01 00 00 00 00 01 39
						39 01 00 00 00 00 01 2C
						39 01 00 00 00 00 03 6D 00 01];
				qcom,mdss-dsi-lp1-command-60nit-state = "dsi_lp_mode";
				qcom,mdss-dsi-lp1-command = [
						15 01 00 00 00 00 02 5A 00
						39 01 00 00 00 00 02 6F 04
						39 01 00 00 00 00 03 51 0F FF
						05 01 00 00 00 00 01 39
						39 01 00 00 00 00 01 2C
						39 01 00 00 00 00 03 6D 00 01];
				qcom,mdss-dsi-lp1-command-state = "dsi_lp_mode";
				qcom,mdss-dsi-nolp-command = [
						05 01 00 00 00 00 01 38
						39 01 00 00 00 00 01 2C
						39 01 00 00 00 00 03 6D 00 00
						15 01 00 00 00 00 02 5A 01];
				qcom,mdss-dsi-nolp-command-state = "dsi_lp_mode";

				qcom,mdss-dsi-h-sync-pulse = <0>;
				qcom,compression-mode = "dsc";
				qcom,mdss-dsc-slice-height = <12>;
				qcom,mdss-dsc-slice-width = <540>;
				qcom,mdss-dsc-slice-per-pkt = <2>;
				qcom,mdss-dsc-bit-per-component = <10>;
				qcom,mdss-dsc-bit-per-pixel = <8>;
				qcom,mdss-dsc-block-prediction-enable;
			};
		};
	};
};
